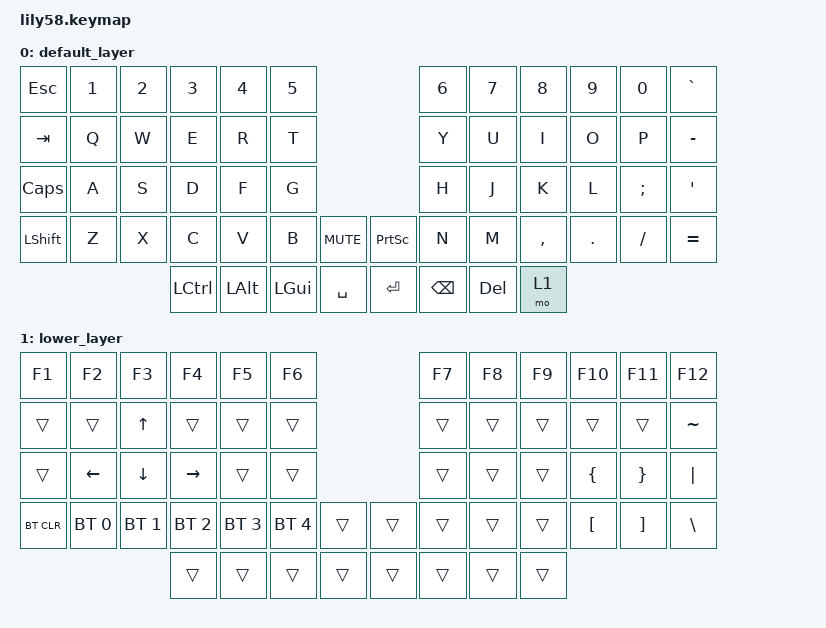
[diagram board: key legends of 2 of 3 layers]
/*
 * Copyright (c) 2020 The ZMK Contributors
 *
 * SPDX-License-Identifier: MIT
 */

#include <behaviors.dtsi>
#include <dt-bindings/zmk/keys.h>
#include <dt-bindings/zmk/bt.h>
#include <dt-bindings/zmk/ext_power.h>
#include <dt-bindings/zmk/rgb.h>
/ {
        // Activate ADJUST layer by pressing raise and lower
    conditional_layers {
        compatible = "zmk,conditional-layers";

        adjust_layer {
            if-layers = <1 2>;
            then-layer = <3>;
        };
    };
    keymap {
        compatible = "zmk,keymap";

        default_layer {
// ------------------------------------------------------------------------------------------------------------
// |  ESC  |  1  |  2  |  3   |  4   |  5   |                   |  6   |  7    |  8    |  9   |   0   |   `   |
// |  TAB  |  Q  |  W  |  E   |  R   |  T   |                   |  Y   |  U    |  I    |  O   |   P   |   -   |
// |  CAPS |  A  |  S  |  D   |  F   |  G   |                   |  H   |  J    |  K    |  L   |   ;   |   '   |
// | SHIFT |  Z  |  X  |  C   |  V   |  B   |  MUTE  |  | PSCRN |  N   |  M    |  ,    |  .   |   /   |   =   |
//                     |LCTRL | ALT  | GUI  |  SPACE |  | ENTER | BSPC | DEL   | LOWER |
            bindings = <
&kp ESC   &kp N1 &kp N2 &kp N3    &kp N4   &kp N5                           &kp N6    &kp N7   &kp N8    &kp N9  &kp N0   &kp GRAVE
&kp TAB   &kp Q  &kp W  &kp E     &kp R    &kp T                            &kp Y     &kp U    &kp I     &kp O   &kp P    &kp MINUS
&kp CAPS  &kp A  &kp S  &kp D     &kp F    &kp G                            &kp H     &kp J    &kp K     &kp L   &kp SEMI &kp SQT
&kp LSHFT &kp Z  &kp X  &kp C     &kp V    &kp B     &kp C_MUTE   &kp PSCRN &kp N     &kp M    &kp COMMA &kp DOT &kp FSLH &kp EQUAL
                        &kp LCTRL &kp LALT &kp LGUI  &kp SPACE    &kp RET   &kp BSPC  &kp DEL  &mo 1
            >;

            sensor-bindings = <&inc_dec_kp C_VOL_UP C_VOL_DN &inc_dec_kp C_PREV C_NEXT>;
        };

        lower_layer {
// ------------------------------------------------------------------------------------------------------------
// |   F1  | F2  | F3  |  F4  |  F5  |  F6  |                   |  F7  |  F8   |  F9   |  F10 |  F11  |  F12  |
// |       |     | UP  |      |      |      |                   |      |       |       |      |       |   ~   |
// |       | LEFT| DOWN| RIGHT|      |      |                   |      |       |       |  {   |   }   |  "|"  |
// | BTCLR | BT1 | BT2 |  BT3 |  BT4 | BT4  |        |  |       |      |       |       |  [   |   ]   |   \   |
//                     |      |      |      |        |  |       |      |       |       |
            bindings = <
&kp F1     &kp F2         &kp F3          &kp F4           &kp F5       &kp F6                          &kp F7    &kp F8    &kp F9    &kp F10   &kp F11   &kp F12
&trans     &trans         &kp UP          &trans           &trans       &trans                          &trans    &trans    &trans    &trans    &trans    &kp TILDE 
&trans     &kp LEFT       &kp DOWN        &kp RIGHT        &trans       &trans                          &trans    &trans    &trans    &kp LBRC  &kp RBRC  &kp PIPE
&bt BT_CLR &bt BT_SEL 0   &bt BT_SEL 1    &bt BT_SEL 2     &bt BT_SEL 3 &bt BT_SEL 4 &trans   &trans    &trans    &trans    &trans    &kp LBKT  &kp RBKT  &kp BSLH
                                          &trans           &trans       &trans       &trans   &trans    &trans    &trans    &trans
            >;

             sensor-bindings = <&inc_dec_kp C_VOL_UP C_VOL_DN &inc_dec_kp C_PREV C_NEXT>;
        };

        adjust_layer {
// ----------------------------------------------------------------------------------------------------------------------------
// | BTCLR  |  BT1    |  BT2    |   BT3   |   BT4   |   BT5   |                  |      |      |       |      |       |       |
// | EXTPWR | RGB_HUD | RGB_HUI | RGB_SAD | RGB_SAI | RGB_EFF |                  |      |      |       |      |       |       |
// |        | RGB_BRD | RGB_BRI |         |         |         |                  |      |      |       |      |       |       |
// |        |         |         |         |         |         |         | |      |      |      |       |      |       |       |
//                    |         |         |         |         |         | |      |      |      |       |      |
            bindings = <
&bt BT_CLR        &bt BT_SEL 0    &bt BT_SEL 1    &bt BT_SEL 2    &bt BT_SEL 3    &bt BT_SEL 4                       &trans &trans &trans &trans &trans &trans
&ext_power EP_TOG &rgb_ug RGB_HUD &rgb_ug RGB_HUI &rgb_ug RGB_SAD &rgb_ug RGB_SAI &rgb_ug RGB_EFF                    &trans &trans &trans &trans &trans &trans
&trans            &rgb_ug RGB_BRD &rgb_ug RGB_BRI &trans           &trans           &trans                           &trans &trans &trans &trans &trans &trans
&trans            &trans          &trans          &trans           &trans           &trans         &trans    &trans  &trans &trans &trans &trans &trans &trans
                                  &trans          &trans           &trans           &trans         &trans    &trans  &trans &trans &trans &trans
            >;
            sensor-bindings = <&inc_dec_kp C_VOL_UP C_VOL_DN>;
        };
         extra1 { status = "reserved"; };

        extra2 { status = "reserved"; };

        extra3 { status = "reserved"; };

        extra4 { status = "reserved"; };

        extra5 { status = "reserved"; };
    };
};
